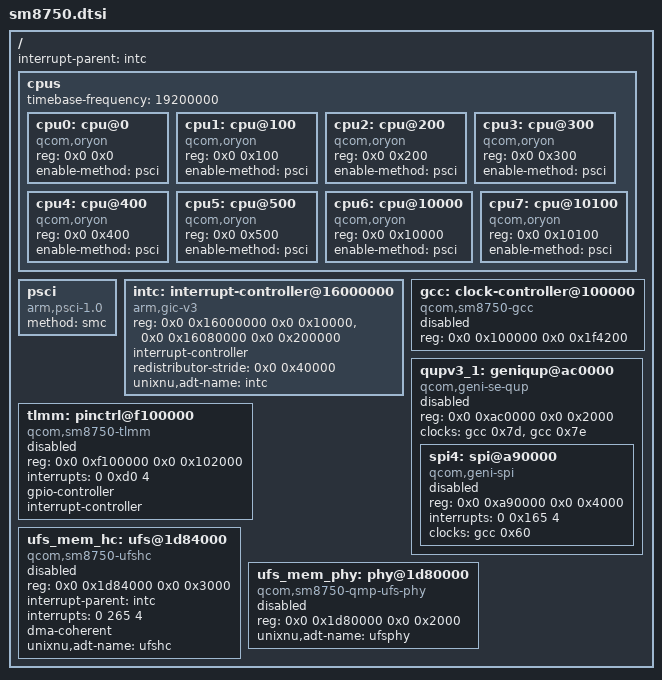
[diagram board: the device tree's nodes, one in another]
// SPDX-License-Identifier: BSD-3-Clause
//
// Minimal SM8750 resources consumed by ArmDTPlatform and ArmCpu.
// Values are based on the public SM8750 Linux device tree. Board-specific
// memory, peripherals and reservations belong in the including device DTS.

/ {
	interrupt-parent = <&intc>;
	#address-cells = <2>;
	#size-cells = <2>;

	cpus {
		#address-cells = <2>;
		#size-cells = <0>;
		timebase-frequency = <19200000>;

		cpu0: cpu@0 {
			device_type = "cpu";
			compatible = "qcom,oryon";
			reg = <0x0 0x0>;
			enable-method = "psci";
		};

		cpu1: cpu@100 {
			device_type = "cpu";
			compatible = "qcom,oryon";
			reg = <0x0 0x100>;
			enable-method = "psci";
		};

		cpu2: cpu@200 {
			device_type = "cpu";
			compatible = "qcom,oryon";
			reg = <0x0 0x200>;
			enable-method = "psci";
		};

		cpu3: cpu@300 {
			device_type = "cpu";
			compatible = "qcom,oryon";
			reg = <0x0 0x300>;
			enable-method = "psci";
		};

		cpu4: cpu@400 {
			device_type = "cpu";
			compatible = "qcom,oryon";
			reg = <0x0 0x400>;
			enable-method = "psci";
		};

		cpu5: cpu@500 {
			device_type = "cpu";
			compatible = "qcom,oryon";
			reg = <0x0 0x500>;
			enable-method = "psci";
		};

		cpu6: cpu@10000 {
			device_type = "cpu";
			compatible = "qcom,oryon";
			reg = <0x0 0x10000>;
			enable-method = "psci";
		};

		cpu7: cpu@10100 {
			device_type = "cpu";
			compatible = "qcom,oryon";
			reg = <0x0 0x10100>;
			enable-method = "psci";
		};
	};

	psci {
		compatible = "arm,psci-1.0";
		method = "smc";
	};

	intc: interrupt-controller@16000000 {
		compatible = "arm,gic-v3";
		reg = <0x0 0x16000000 0x0 0x10000>,
		      <0x0 0x16080000 0x0 0x200000>;
		interrupt-controller;
		#interrupt-cells = <3>;
		redistributor-stride = <0x0 0x40000>;
		unixnu,adt-name = "intc";
	};

	gcc: clock-controller@100000 {
		compatible = "qcom,sm8750-gcc";
		reg = <0x0 0x100000 0x0 0x1f4200>;
		#clock-cells = <1>;
		status = "disabled";
	};

	qupv3_1: geniqup@ac0000 {
		compatible = "qcom,geni-se-qup";
		reg = <0x0 0xac0000 0x0 0x2000>;
		clocks = <&gcc 0x7d>, <&gcc 0x7e>;
		clock-names = "m-ahb", "s-ahb";
		#address-cells = <2>;
		#size-cells = <2>;
		ranges;
		status = "disabled";

		spi4: spi@a90000 {
			compatible = "qcom,geni-spi";
			reg = <0x0 0xa90000 0x0 0x4000>;
			interrupts = <0 0x165 4>;
			clocks = <&gcc 0x60>;
			clock-names = "se";
			#address-cells = <1>;
			#size-cells = <0>;
			status = "disabled";
		};
	};

	tlmm: pinctrl@f100000 {
		compatible = "qcom,sm8750-tlmm";
		reg = <0x0 0xf100000 0x0 0x102000>;
		interrupts = <0 0xd0 4>;
		gpio-controller;
		#gpio-cells = <2>;
		interrupt-controller;
		#address-cells = <0>;
		#interrupt-cells = <2>;
		status = "disabled";
	};

	// UFS host controller and QMP PHY. Values come from the public SM8750
	// Linux tree; the board DTS enables them.
	//
	// These nodes describe the hardware for the ADT and for review, not the
	// complete driver contract: the current ShengUfs/NativeUfs driver uses
	// fixed SM8750 constants (host 0x1d84000, GCC 0x100000, SMMU 0x15000000,
	// stream 0x60) rather than reading them from the device tree. Clocks,
	// resets, power domains, SMMU stream and ICE are therefore not listed as
	// properties yet - they would reference providers this source does not
	// describe, and the ADT generator drops reference properties whose target
	// node is missing. docs/PHASE3-STORAGE.md records the full inventory.
	ufs_mem_hc: ufs@1d84000 {
		compatible = "qcom,sm8750-ufshc", "qcom,ufshc", "jedec,ufs-2.0";
		reg = <0x0 0x1d84000 0x0 0x3000>;
		interrupt-parent = <&intc>;
		interrupts = <0 265 4>;
		dma-coherent;
		unixnu,adt-name = "ufshc";
		status = "disabled";
	};

	ufs_mem_phy: phy@1d80000 {
		compatible = "qcom,sm8750-qmp-ufs-phy";
		reg = <0x0 0x1d80000 0x0 0x2000>;
		unixnu,adt-name = "ufsphy";
		status = "disabled";
	};
};
